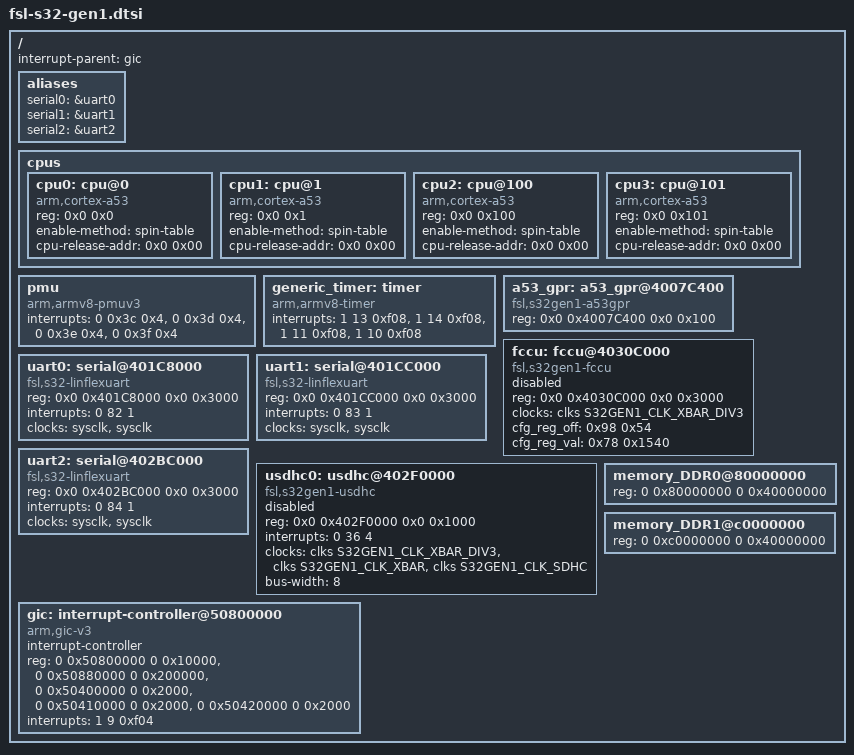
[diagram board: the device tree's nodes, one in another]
/*
 * Copyright 2017-2020 NXP
 *
 * This program is free software; you can redistribute it and/or modify
 * it under the terms of the GNU General Public License as published by
 * the Free Software Foundation; either version 2 of the License, or
 * (at your option) any later version.
 */

/memreserve/ 0x8000fff8 0x00010000;

/ {
	interrupt-parent = <&gic>;
	#address-cells = <2>;
	#size-cells = <2>;

	aliases {
		serial0 = &uart0;
		serial1 = &uart1;
		serial2 = &uart2;
	};

	cpus {
		#address-cells = <2>;
		#size-cells = <0>;

		cpu0: cpu@0 {
			device_type = "cpu";
			compatible = "arm,cortex-a53";
			reg = <0x0 0x0>;
			enable-method = "spin-table";
			cpu-release-addr = <0x0 0x00>;
		};
		cpu1: cpu@1 {
			device_type = "cpu";
			compatible = "arm,cortex-a53";
			reg = <0x0 0x1>;
			enable-method = "spin-table";
			cpu-release-addr = <0x0 0x00>;
		};
		cpu2: cpu@100 {
			device_type = "cpu";
			compatible = "arm,cortex-a53";
			reg = <0x0 0x100>;
			enable-method = "spin-table";
			cpu-release-addr = <0x0 0x00>;
		};
		cpu3: cpu@101 {
			device_type = "cpu";
			compatible = "arm,cortex-a53";
			reg = <0x0 0x101>;
			enable-method = "spin-table";
			cpu-release-addr = <0x0 0x00>;
		};

	};

	pmu {
		compatible = "arm,armv8-pmuv3";
		interrupts = <0 0x3c 0x4>,
			     <0 0x3d 0x4>,
			     <0 0x3e 0x4>,
			     <0 0x3f 0x4>;
	};

	generic_timer: timer {
		compatible = "arm,armv8-timer";
		interrupts = <1 13 0xf08>,
			     <1 14 0xf08>,
			     <1 11 0xf08>,
			     <1 10 0xf08>;
	};

	a53_gpr: a53_gpr@4007C400 {
		compatible = "fsl,s32gen1-a53gpr";
		reg = <0x0 0x4007C400 0x0 0x100>;
	};

	fccu: fccu@4030C000 {
		compatible = "fsl,s32gen1-fccu";
		reg = <0x0 0x4030C000 0x0 0x3000>;
		clocks = <&clks S32GEN1_CLK_XBAR_DIV3>;
		clock-names = "fccu";
		/* Address offset and configuration value for */
		/* NCF_E1 and NCFS_CFG2*/
		cfg_reg_off = <0x98 0x54>;
		cfg_reg_val = <0x78 0x1540>;
		status = "disabled";
	};

	uart0:serial@401C8000 {
		compatible = "fsl,s32-linflexuart";
		reg = <0x0 0x401C8000 0x0 0x3000>;
		interrupts = <0 82 1>;
		clocks = <&sysclk>, <&sysclk>;
		clock-names = "lin", "ipg";
	};

	uart1:serial@401CC000 {
		compatible = "fsl,s32-linflexuart";
		reg = <0x0 0x401CC000 0x0 0x3000>;
		interrupts = <0 83 1>;
		clocks = <&sysclk>, <&sysclk>;
		clock-names = "lin", "ipg";
	};

	uart2:serial@402BC000 {
		compatible = "fsl,s32-linflexuart";
		reg = <0x0 0x402BC000 0x0 0x3000>;
		interrupts = <0 84 1>;
		clocks = <&sysclk>, <&sysclk>;
		clock-names = "lin", "ipg";
	};

	usdhc0: usdhc@402F0000{
		compatible = "fsl,s32gen1-usdhc";
		reg = <0x0 0x402F0000 0x0 0x1000>;
		interrupts = <0 36 4>;
		clocks = <&clks S32GEN1_CLK_XBAR_DIV3>,
			 <&clks S32GEN1_CLK_XBAR>,
			 <&clks S32GEN1_CLK_SDHC>;
		clock-names = "ipg", "ahb", "per";
		bus-width = <8>;
		status = "disabled";
	};

	gic: interrupt-controller@50800000 {
		compatible = "arm,gic-v3";
		#interrupt-cells = <3>;
		#address-cells = <2>;
		#size-cells = <2>;
		interrupt-controller;
		reg = <0 0x50800000 0 0x10000>,
		      <0 0x50880000 0 0x200000>,
		      <0 0x50400000 0 0x2000>,
		      <0 0x50410000 0 0x2000>,
		      <0 0x50420000 0 0x2000>;
		interrupts = <1 9 0xf04>;
	};

	memory_DDR0@80000000 {
		device_type = "memory";
		reg = <0 0x80000000 0 0x40000000>;
	};

	memory_DDR1@c0000000 {
		device_type = "memory";
		reg = <0 0xc0000000 0 0x40000000>;
	};
};
